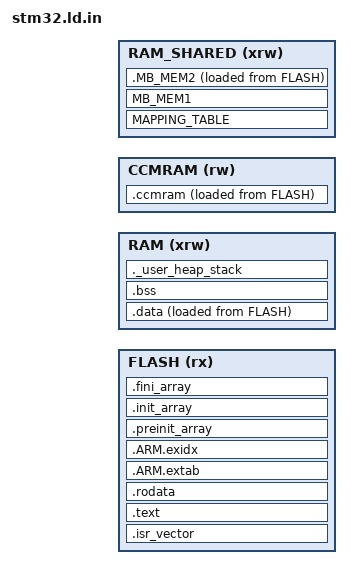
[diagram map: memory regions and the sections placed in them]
ENTRY(Reset_Handler)

_Min_Heap_Size = @min_heap_size@;
_Min_Stack_Size = @min_stack_size@;

MEMORY
{
  FLASH (rx)      : ORIGIN = @flash_origin@, LENGTH = @flash_length@
  RAM (xrw)       : ORIGIN = @ram_origin@, LENGTH = @ram_length@
@if ccmram_length@
  CCMRAM (rw)     : ORIGIN = @ccmram_origin@, LENGTH = @ccmram_length@
@endif@
@if shared_ram_length@
  RAM_SHARED (xrw): ORIGIN = @shared_ram_origin@, LENGTH = @shared_ram_length@
@endif@
}

_estack = ORIGIN(RAM) + LENGTH(RAM);
_sstack = _estack - _Min_Stack_Size;

SECTIONS
{
  .isr_vector :
  {
    . = ALIGN(4);
    KEEP(*(.isr_vector))
    . = ALIGN(4);
  } >FLASH

  .text :
  {
    . = ALIGN(4);
    *(.text)
    *(.text*)
    *(.glue_7)
    *(.glue_7t)
    *(.eh_frame)

    KEEP (*(.init))
    KEEP (*(.fini))

    . = ALIGN(4);
    _etext = .;
  } >FLASH

  .rodata :
  {
    . = ALIGN(4);
    *(.rodata)
    *(.rodata*)
    . = ALIGN(4);
  } >FLASH

  .ARM.extab   : { *(.ARM.extab* .gnu.linkonce.armextab.*) } >FLASH
  .ARM.exidx   : { *(.ARM.exidx* .gnu.linkonce.armexidx.*) } >FLASH

  .preinit_array :
  {
    PROVIDE_HIDDEN (__preinit_array_start = .);
    KEEP (*(.preinit_array*))
    PROVIDE_HIDDEN (__preinit_array_end = .);
  } >FLASH
  .init_array :
  {
    PROVIDE_HIDDEN (__init_array_start = .);
    KEEP (*(SORT(.init_array.*)))
    KEEP (*(.init_array*))
    PROVIDE_HIDDEN (__init_array_end = .);
  } >FLASH
  .fini_array :
  {
    PROVIDE_HIDDEN (__fini_array_start = .);
    KEEP (*(SORT(.fini_array.*)))
    KEEP (*(.fini_array*))
    PROVIDE_HIDDEN (__fini_array_end = .);
  } >FLASH

  _sidata = LOADADDR(.data);

  .data :
  {
    . = ALIGN(4);
    _sdata = .;
    *(.data)
    *(.data*)
    . = ALIGN(4);
    _edata = .;
  } >RAM AT> FLASH

@if ccmram_length@
  _siccmram = LOADADDR(.ccmram);

  .ccmram :
  {
    . = ALIGN(4);
    _sccmram = .;
    *(.ccmram)
    *(.ccmram*)
    . = ALIGN(4);
    _eccmram = .;
  } >CCMRAM AT> FLASH

@endif@
  .bss :
  {
    . = ALIGN(4);
    _sbss = .;
    __bss_start__ = _sbss;
    *(.bss)
    *(.bss*)
    *(COMMON)
    . = ALIGN(4);
    _ebss = .;
    __bss_end__ = _ebss;
  } >RAM

  ._user_heap_stack :
  {
    . = ALIGN(8);
    PROVIDE ( end = . );
    PROVIDE ( _end = . );
    . = . + _Min_Heap_Size;
    . = . + _Min_Stack_Size;
    . = ALIGN(8);
  } >RAM

  /DISCARD/ :
  {
    libc.a ( * )
    libm.a ( * )
    libgcc.a ( * )
  }

@if shared_ram_length@
  MAPPING_TABLE (NOLOAD) : { *(MAPPING_TABLE) } >RAM_SHARED
  MB_MEM1 (NOLOAD)       : { *(MB_MEM1) } >RAM_SHARED

  _siMB_MEM2 = LOADADDR(.MB_MEM2);
  .MB_MEM2 :
  {
    _sMB_MEM2 = . ;
    *(MB_MEM2) ;
    _eMB_MEM2 = . ;
  } >RAM_SHARED AT> FLASH

@endif@
  .ARM.attributes 0 : { *(.ARM.attributes) }
}
